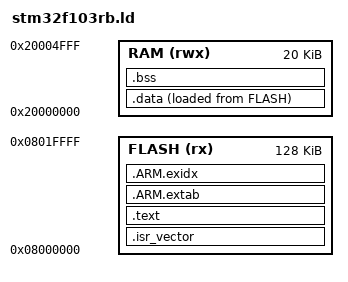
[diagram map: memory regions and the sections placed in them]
ENTRY(Reset_Handler)
MEMORY {
 FLASH (rx) : ORIGIN = 0x08000000, LENGTH = 128K
 RAM (rwx) : ORIGIN = 0x20000000, LENGTH = 20K
}
_estack = ORIGIN(RAM) + LENGTH(RAM);
SECTIONS {
 .isr_vector : { KEEP(*(.isr_vector)) } > FLASH
 .text : { *(.text*) *(.rodata*) . = ALIGN(4); } > FLASH
 .ARM.extab : { *(.ARM.extab*) } > FLASH
 .ARM.exidx : { *(.ARM.exidx*) } > FLASH
 .data : { . = ALIGN(4); _sdata = .; *(.data*) . = ALIGN(4); _edata = .; } > RAM AT > FLASH
 _sidata = LOADADDR(.data);
 .bss (NOLOAD) : { . = ALIGN(8); _sbss = .; *(.bss*) *(COMMON) . = ALIGN(8); _ebss = .; } > RAM
 _end = .;
 ASSERT(_ebss <= _estack - 2048, "Reserve 2 KiB for main/interrupt stack")
}
